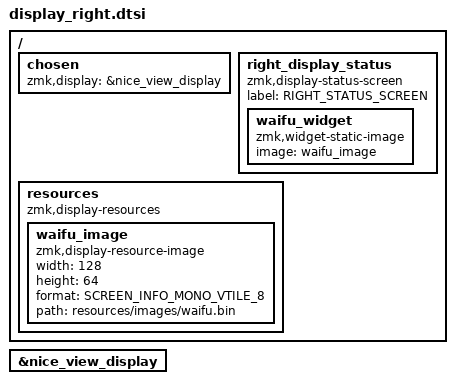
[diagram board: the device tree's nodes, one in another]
#include <zephyr/dt-bindings/display/screen_info.h>

/ {
    chosen {
        zmk,display = &nice_view_display;
    };
};

&nice_view_display {
    status = "okay";
};

/ {
    // Define your custom right display status screen
    right_display_status: right_display_status {
        compatible = "zmk,display-status-screen";
        label = "RIGHT_STATUS_SCREEN";
        status = "okay";
        
        waifu_widget: waifu_widget {
            compatible = "zmk,widget-static-image";
            status = "okay";
            image = <&waifu_image>;
        };
    };
    
    // Define the image resource with corrected name
    resources {
        compatible = "zmk,display-resources";
        
        waifu_image: waifu_image {
            compatible = "zmk,display-resource-image";
            width = <128>;
            height = <64>;
            format = <SCREEN_INFO_MONO_VTILE_8>;
            path = "resources/images/waifu.bin";
        };
    };
};
